# XMC1300 register map
Vendor: Infineon; File version: 1.2.2 (Reference Manual v1.2)
SVD file
CPU: CM0 r0p0, little endian, no MPU, no FPU, 2 interrupt priority bits
Registers are 32-bit, read-write, reset 0x0 unless marked. A register's access mark holds for its fields unless they carry their own. Offsets are from the block's base; lines under a group give offsets from that group; [hi:lo] are bit positions; {n}, {i} and the like mark numbered series; 'fields as' and 'values as' point back to an identical list; <NAME> marks a mode.

## Memory map
0x40000000 PAU size 0x10000 — PAU Unit
0x40010000 SCU_GENERAL size 0x200 — System Control Unit
0x40010038 SCU_INTERRUPT size 0xF — System Control Unit
0x40010200 SCU_POWER size 0x100 — System Control Unit
0x40010300 SCU_CLK size 0x100 — System Control Unit
0x40010400 SCU_RESET size 0x100 — System Control Unit
0x40010500 COMPARATOR size 0xC00 — System Control Unit
0x40010600 ERU0 size 0x100 — Event Request Unit 0
0x40010A00 RTC size 0x100 — Real Time Clock
0x40011000 SCU_ANALOG size 0x100 — System Control Unit
0x40020000 WDT size 0x10000 — Watch Dog Timer
0x40030000 MATH size 0x60 — MATH Unit
0x40040000 PORT0 size 0x100
0x40040100 PORT1 size 0x100
0x40040200 PORT2 size 0x100
0x40050000 NVM size 0x100 — NVM Unit
0x48000000 USIC0_CH0 size 0x200 — Universal Serial Interface Controller 0
0x48000008 USIC0 size 0x4 — Universal Serial Interface Controller 0
0x48000200 USIC0_CH1 size 0x200 — Universal Serial Interface Controller 0
0x48020000 PRNG size 0x10 — PRNG Unit
0x48030000 VADC size 0x400 — Analog to Digital Converter
0x48030400 VADC_G0 size 0x400 — Analog to Digital Converter
0x48030800 VADC_G1 size 0x400 — Analog to Digital Converter
0x48034000 SHS0 size 0x200 — Sample and Hold ADC Sequencer
0x48040000 CCU40 size 0x10000 — Capture Compare Unit 4 - Unit 0
0x48040100 CCU40_CC40 size 0x100 — Capture Compare Unit 4 - Unit 0
0x48040200 CCU40_CC41 size 0x100 — Capture Compare Unit 4 - Unit 0
0x48040300 CCU40_CC42 size 0x100 — Capture Compare Unit 4 - Unit 0
0x48040400 CCU40_CC43 size 0x100 — Capture Compare Unit 4 - Unit 0
0x50000000 CCU80 size 0x10000 — Capture Compare Unit 8 - Unit 0
0x50000100 CCU80_CC80 size 0x100 — Capture Compare Unit 8 - Unit 0
0x50000200 CCU80_CC81 size 0x100 — Capture Compare Unit 8 - Unit 0
0x50000300 CCU80_CC82 size 0x100 — Capture Compare Unit 8 - Unit 0
0x50000400 CCU80_CC83 size 0x100 — Capture Compare Unit 8 - Unit 0
0x50010000 POSIF0 size 0x10000 — Position Interface 0
0x50030000 BCCU0 size 0x3C — BCCU Unit 0
{0x5003003C+0x14*n} BCCU0_CH{n} size 0x14 (n=0..8) — BCCU Unit 0
0x5003017C BCCU0_DE0 size 0xC — BCCU Unit 0
0x50030188 BCCU0_DE1 size 0xC — BCCU Unit 0
0x50030194 BCCU0_DE2 size 0xC — BCCU Unit 0
0xE000E000 PPB size 0x1000 — Cortex-M0 Private Peripheral Block

## ERU0 — Event Request Unit 0
Base 0x40010600
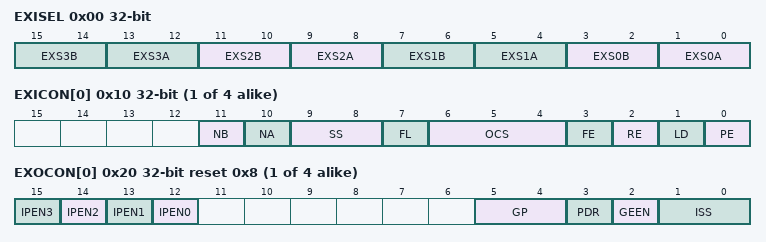
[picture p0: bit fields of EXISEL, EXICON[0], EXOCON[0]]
0x00 EXISEL — Event Input Select
  [4n+3:4n+2] EXS{n}B (n=0..3) — Event Source Select for B{n} (ERS{n})
    {v}=Input ERU_{n}B{v} is selected (v=0..3)
  [4n+1:4n] EXS{n}A (n=0..3) — Event Source Select for A{n} (ERS{n})
    {v}=Input ERU_{n}A{v} is selected (v=0..3)
{0x10+4i} EXICON[{i}] (i=0..3) — Event Input Control
  [11] NB — Input B Negation Select for ERSx
    0=Input B is used directly; 1=Input B is inverted
  [10] NA — Input A Negation Select for ERSx
    0=Input A is used directly; 1=Input A is inverted
  [9:8] SS — Input Source Select for ERSx
    0=Input A without additional combination; 1=Input B without additional combination; 2=Input A OR input B; 3=Input A AND input B
  [7] FL — Status Flag for ETLx
    0=The enabled edge event has not been detected; 1=The enabled edge event has been detected
  [6:4] OCS — Output Channel Select for ETLx Output Trigger Pulse
    {v}=Trigger pulses are sent to OGU{v} (v=0..3)
  [3] FE — Falling Edge Detection Enable ETLx
    0=A falling edge is not considered as edge event; 1=A falling edge is considered as edge event
  [2] RE — Rising Edge Detection Enable ETLx
    0=A rising edge is not considered as edge event; 1=A rising edge is considered as edge event
  [1] LD — Rebuild Level Detection for Status Flag for ETLx
    0=The status flag FL is not cleared by hardware and is used as "sticky" bit. Once set, it is not influenced by any edge until it becomes cleared by software.; 1=The status flag FL rebuilds a level detection of the desired event. It becomes automatically set with a rising edge if RE = 1 or with a falling edge if FE = 1. It becomes automatically cleared with a rising edge if RE = 0 or with a falling edge if FE = 0.
  [0] PE — Output Trigger Pulse Enable for ETLx
    0=The trigger pulse generation is disabled; 1=The trigger pulse generation is enabled
{0x20+4i} EXOCON[{i}] (i=0..3) access per field reset 0x8 — Event Output Trigger Control
  [n+12] IPEN{n} rw (n=0..3) — Pattern Detection Enable for ETL{n}
    0=Flag EXICONx.FL is excluded from the pattern detection; 1=Flag EXICONx.FL is included in the pattern detection
  [5:4] GP rw — Gating Selection for Pattern Detection Result
    0=ERU_GOUTy is always disabled and ERU_IOUTy can not be activated; 1=ERU_GOUTy is always enabled and ERU_IOUTy becomes activated with each activation of ERU_TOUTy; 2=ERU_GOUTy is equal to ERU_PDOUTy and ERU_IOUTy becomes activated with an activation of ERU_TOUTy while the desired pattern is detected (pattern match PDR = 1); 3=ERU_GOUTy is inverted to ERU_PDOUTy and ERU_IOUTy becomes activated with an activation of ERU_TOUTy while the desired pattern is not detected (pattern miss PDR = 0)
  [3] PDR ro — Pattern Detection Result Flag
    0=A pattern miss is detected; 1=A pattern match is detected
  [2] GEEN rw — Gating Event Enable
    0=The event detection is disabled; 1=The event detection is enabled
  [1:0] ISS rw — Internal Trigger Source Selection
    0=The peripheral trigger function is disabled; 1=Input ERU_OGUy1 is selected; 2=Input ERU_OGUy2 is selected; 3=Input ERU_OGUy3 is selected

## Notices in the file
Copyright (C) 2012 Infineon Technologies AG. All rights reserved.
Infineon Technologies AG (Infineon) is supplying this software for use with
Infineon's microcontrollers.  This file can be freely distributed within
development tools that are supporting such microcontrollers.
THIS SOFTWARE IS PROVIDED "AS IS".  NO WARRANTIES, WHETHER EXPRESS, IMPLIED
OR STATUTORY, INCLUDING, BUT NOT LIMITED TO, IMPLIED WARRANTIES OF
MERCHANTABILITY AND FITNESS FOR A PARTICULAR PURPOSE APPLY TO THIS SOFTWARE.
INFINEON SHALL NOT, IN ANY CIRCUMSTANCES, BE LIABLE FOR SPECIAL, INCIDENTAL,
OR CONSEQUENTIAL DAMAGES, FOR ANY REASON WHATSOEVER.
